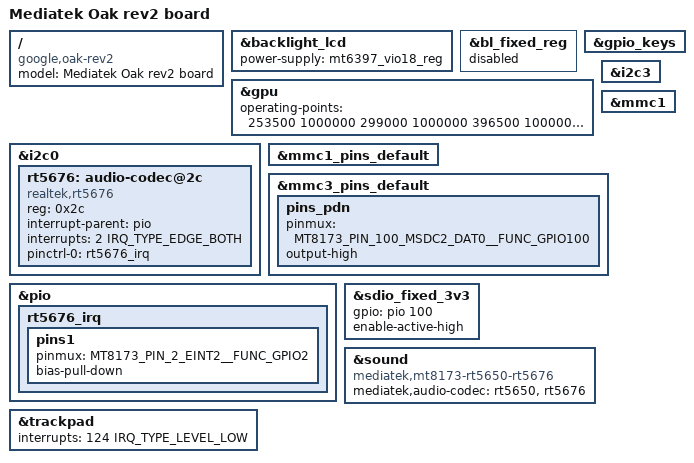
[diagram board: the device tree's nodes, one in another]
/*
 * Copyright 2015 MediaTek Inc.
 * Author: Eddie Huang <eddie.huang@mediatek.com>
 *
 * This program is free software; you can redistribute it and/or modify
 * it under the terms of the GNU General Public License version 2 as
 * published by the Free Software Foundation.
 *
 * This program is distributed in the hope that it will be useful,
 * but WITHOUT ANY WARRANTY; without even the implied warranty of
 * MERCHANTABILITY or FITNESS FOR A PARTICULAR PURPOSE.  See the
 * GNU General Public License for more details.
 */

/dts-v1/;
#include "mt8173-oak.dtsi"

/ {
	model = "Mediatek Oak rev2 board";
	compatible = "google,oak-rev2", "google,oak", "mediatek,mt8173";
};

&backlight_lcd {
	power-supply = <&mt6397_vio18_reg>;
};

&bl_fixed_reg {
	status = "disabled";
};

&gpio_keys {
	/delete-property/pinctrl-names;
	/delete-property/pinctrl-0;

	/delete-node/tablet_mode;
	/delete-node/volume_down;
	/delete-node/volume_up;
};

&gpu {
	operating-points = <
		253500 1000000
		299000 1000000
		396500 1000000
		455000 1000000
		494000 1130000
	>;
};

&i2c0 {
	rt5676: audio-codec@2c {
		compatible = "realtek,rt5676";
		reg = <0x2c>;
		interrupt-parent = <&pio>;
		interrupts = <2 IRQ_TYPE_EDGE_BOTH>;
		pinctrl-names = "default";
		pinctrl-0 = <&rt5676_irq>;
	};
};

&i2c3 {
	/delete-node/touchscreen@10;
};

&mmc1 {
	/delete-property/wp-gpios;
};

&mmc1_pins_default {
	/delete-node/pins_wp;
};

&mmc3_pins_default {
	pins_pdn {
		pinmux = <MT8173_PIN_100_MSDC2_DAT0__FUNC_GPIO100>;
		output-high;
	};
};

&pio {
	/delete-node/gpio_keys_node;

	rt5676_irq: rt5676_irq {
		pins1 {
			pinmux = <MT8173_PIN_2_EINT2__FUNC_GPIO2>;
			bias-pull-down;
		};
	};
};

&sdio_fixed_3v3 {
	gpio = <&pio 100 GPIO_ACTIVE_HIGH>;
	enable-active-high;
};

&sound {
	compatible = "mediatek,mt8173-rt5650-rt5676";
	mediatek,audio-codec = <&rt5650 &rt5676>;
};

&trackpad {
	interrupts = <124 IRQ_TYPE_LEVEL_LOW>;
};
